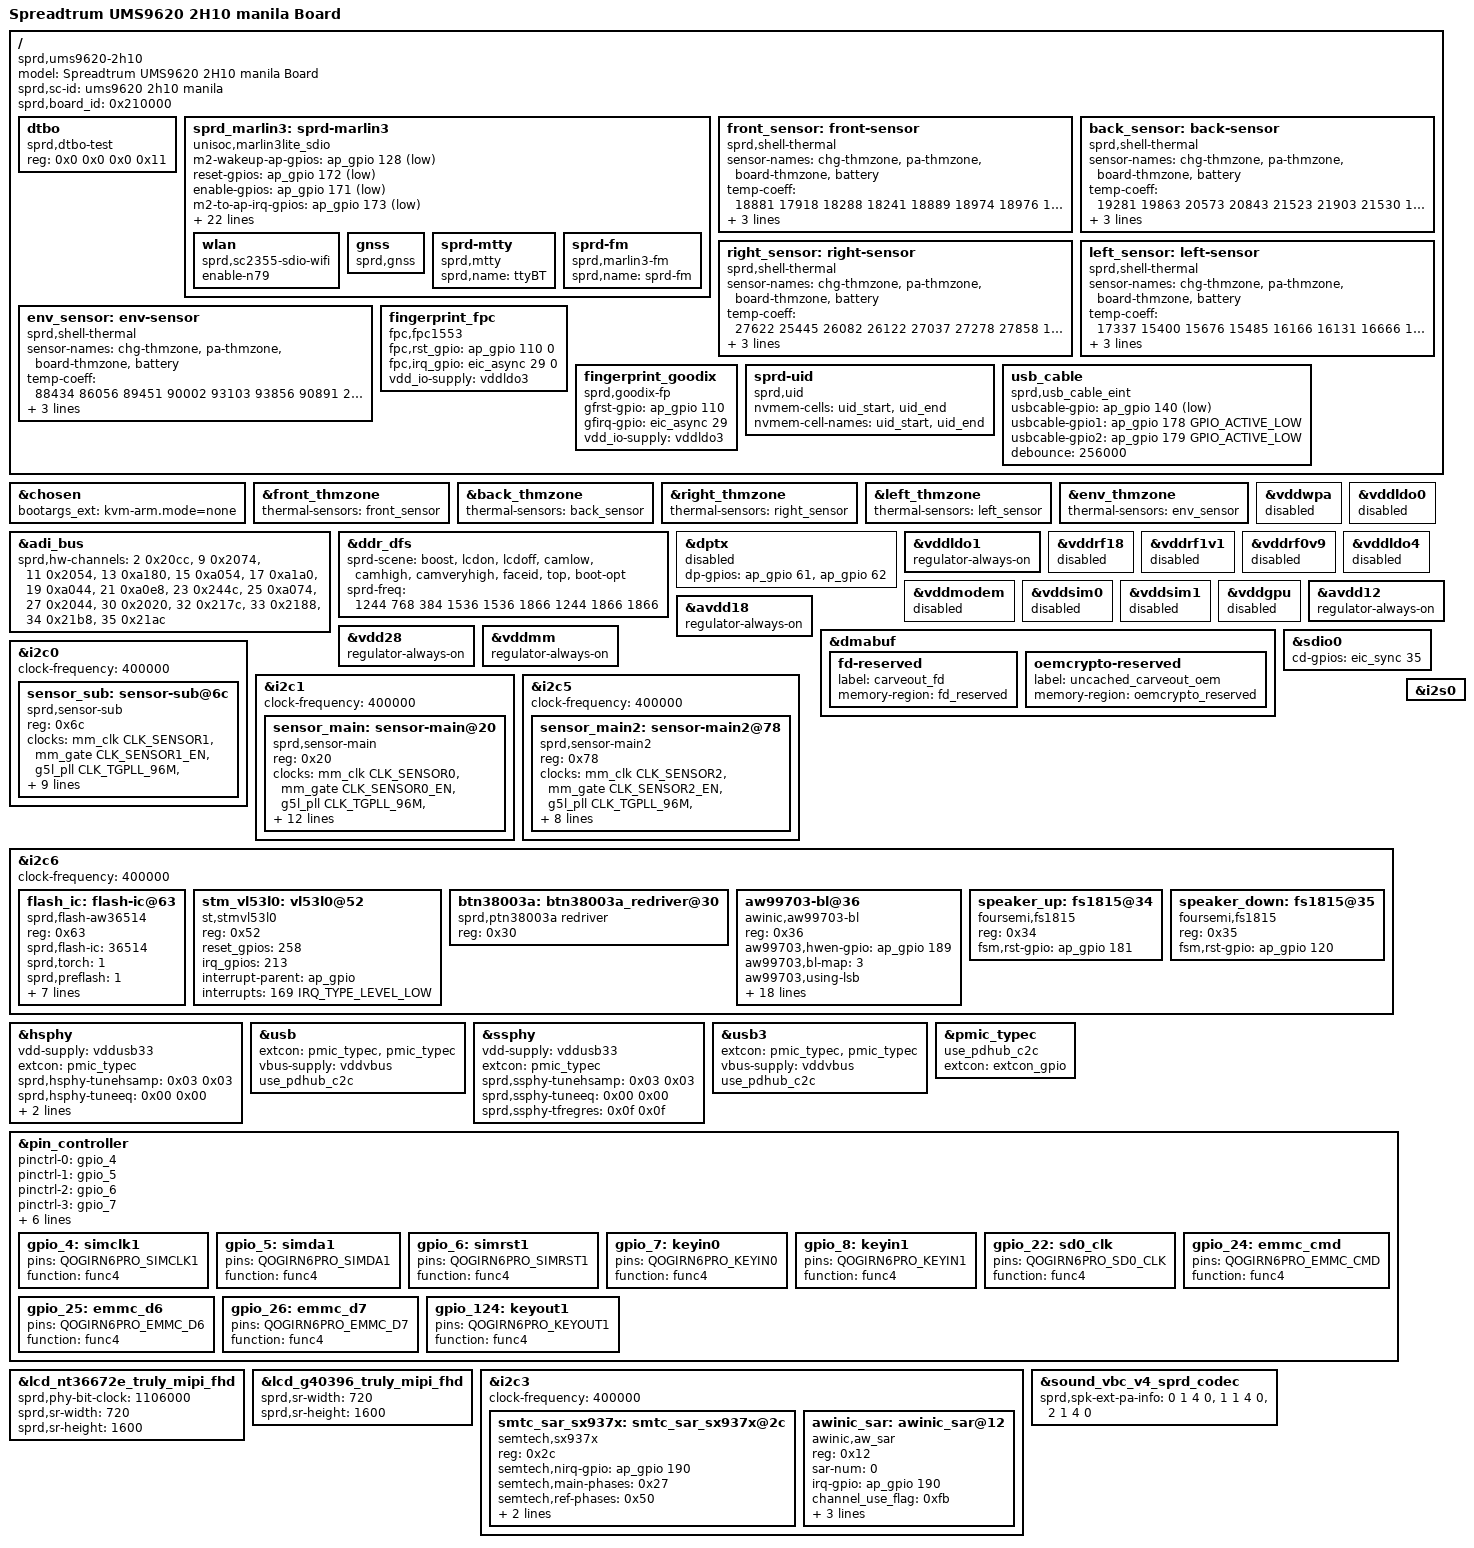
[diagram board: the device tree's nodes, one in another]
// SPDX-License-Identifier: (Licenseref-Unisoc-General-1.0 OR GPL-2.0-only)
/*
 * ums9620-2h10-overlay.dts - Unisoc platform device
 *
 * Copyright 2022 Unisoc(Shanghai) Technologies Co.Ltd
 *
 * Licensed under the Unisoc General Software License, version 1.0 (the
 * License);
 * you may not use this file except in compliance with the License.
 * You may obtain a copy of the License at
 * https://www.unisoc.com/en_us/license/UNISOC_GENERAL_LICENSE_V1.0-EN_US
 * Software distributed under the License is distributed on an "AS IS" BASIS,
 * WITHOUT WARRANTIES OF ANY KIND, either express or implied.
 * See the Unisoc General Software License, version 1.0 for more details.
 *
 * Alternatively you can use and distribute this file under the terms of the
 * GNU General Public License version 2, provided that it has to be used
 *  (including but not limited to combining, linking) with any other file under
 * the GNU General Public License version 2 on platforms that use Unisoc Chips.
 */

/dts-v1/;
/plugin/;
#include <dt-bindings/gpio/gpio.h>
#include <dt-bindings/interrupt-controller/arm-gic.h>
#include <dt-bindings/clock/sprd,ums9620-clk.h>
#include <dt-bindings/usb/pd.h>
#include "lcd/amoled_g2667fp108ff_visionox_mipi_fhd.dtsi"
#include "lcd/lcd_g40396_truly_mipi_fhd.dtsi"
#include "lcd/lcd_nt36672e_truly_mipi_fhd.dtsi"
#include "lcd/lcd_nt36672c_truly_mipi_fhd.dtsi"
#include "lcd/lcd_td4320_truly_mipi_fhd.dtsi"
#include "lcd/lcd_td4375_dijin_4lane_mipi_fhd.dtsi"
#include "lcd/lcd_ili9883c_txd_120hz_mipi_hd.dtsi"
#include "lcd/lcd_dummy_mipi.dtsi"
#include "reserved-memory/ums9620-2h10-overlay.dtsi"
#include "touchscreen/ums9620-spi1-gpio13-14-tp.dtsi"
#include "battery/ums9620-2h10_manila-overlay.dtsi"
#include "sound/ums9620-overlay.dtsi"
#include <dt-bindings/mfd/sprd,ump9620-regs.h>
#include <dt-bindings/mfd/sprd,ump9620-mask.h>
#include <dt-bindings/input/input.h>
#include <dt-bindings/clock/sprd,ums9620-clk.h>
#include "wcn/wcn_modules.h"
#include "wcn/interface/wcn-sdio-register.dtsi"
#include "wcn/chip/wcn-marlin3lite-umw2652-register.dtsi"

/ {

	model = "Spreadtrum UMS9620 2H10 manila Board"; // ONTIM

	compatible = "sprd,ums9620-2h10", "sprd,ums9620";

	sprd,sc-id = "ums9620 2h10 manila"; // ONTIM

	sprd,board_id = <0x210000>; //XXYY00:base board,XXYY00~XXYYFF:customize board

	fragment {
		target-path = "/";
		__overlay__ {
			#address-cells = <2>;
			#size-cells = <2>;

			model = "Spreadtrum UMS9620 2H10 manila Board"; // ONTIM
			sprd,sc-id = "ums9620 2h10 manila"; // ONTIM

			dtbo: dtbo {
				compatible = "sprd,dtbo-test";
				reg = <0x0 0x0 0x0 0x11>;
			};
			sprd_marlin3: sprd-marlin3 {
				compatible = "unisoc,marlin3lite_sdio";
				m2-wakeup-ap-gpios = <&ap_gpio 128 GPIO_ACTIVE_LOW>;
				reset-gpios = <&ap_gpio 172 GPIO_ACTIVE_LOW>;
				enable-gpios = <&ap_gpio 171 GPIO_ACTIVE_LOW>;
				m2-to-ap-irq-gpios = <&ap_gpio 173 GPIO_ACTIVE_LOW>;
				/* xtal-26m-clk-type = "TCXO"; */
				avdd12-supply = <&vddwcn>;
				avdd33-supply = <&vddwifipa>;
				dcxo18-supply = <&vddsim2>;
				clock-names = "clk_32k","source","enable";
				clocks = <&aonapb_gate CLK_AUX0>,
					 <&ext_32k>,
					 <&aonapb_gate CLK_AUX0_EB>;
				extcon = <&sdio1>;
				sdhci-name = <&sdio1>;
				sprd,check-emmc-ufs = "need_to_check_emmc_or_ufs";
				sprd,btwf-file-name = "/dev/block/by-name/wcnmodem";
				sprd,gnss-file-name = "/vendor/firmware/gnssmodem.bin";
				btwf-wakeup-lock;
				adma-tx;
				adma-rx;
				n79-mode-support;
				/*
				 * bound parameter:
				 * [0]:addr offset, [1]:mask, [2]:unboundval, [3]:boundval
				 */
				avdd12-parent-bound-chip = <REG_ANA_SLP_DCDC_PD_CTRL MASK_ANA_SLP_DCDCGEN1_PD_EN 0x0 MASK_ANA_SLP_DCDCGEN1_PD_EN>;
				avdd12-bound-wbreq = <REG_ANA_LDO_XTL_EN10 MASK_ANA_LDO_VDDWCN_EXT_XTL3_EN 0x0 MASK_ANA_LDO_VDDWCN_EXT_XTL3_EN>;
				avdd33-bound-wbreq = <REG_ANA_LDO_XTL_EN11 MASK_ANA_LDO_VDDWIFIPA_EXT_XTL3_EN 0x0 MASK_ANA_LDO_VDDWIFIPA_EXT_XTL3_EN>;

				wlan {
					compatible = "sprd,sc2355-sdio-wifi";
					enable-n79;
				};

				gnss {
					compatible = "sprd,gnss";
				};

				sprd-mtty {
					compatible = "sprd,mtty";
					sprd,name = "ttyBT";
				};

				sprd-fm {
					compatible = "sprd,marlin3-fm";
					sprd,name = "sprd-fm";
				};
			};

			front_sensor: front-sensor {
				compatible = "sprd,shell-thermal";
				#thermal-sensor-cells = <0>;
				sensor-names = "chg-thmzone",
						"pa-thmzone",
						"board-thmzone",
						"battery";
				temp-coeff = <18881 17918 18288 18241 18889 18974 18976
						13160 17177 17571 17413 17324 17990 23386
						15219 15341 15299 15330 14777 13891 16130
						597 16326 16001 15710 19060 19947 38182>;
				coeff-offset = <17000>;
				temp-const = <256>;
				const-offset = <0>;
			};

			back_sensor: back-sensor {
				compatible = "sprd,shell-thermal";
				#thermal-sensor-cells = <0>;
				sensor-names = "chg-thmzone",
						"pa-thmzone",
						"board-thmzone",
						"battery";
				temp-coeff = <19281 19863 20573 20843 21523 21903 21530
						15641 19803 20542 20460 20374 21149 27280
						20678 19833 19152 18770 18146 17276 19273
						521 18852 18577 18451 22329 23133 44243>;
				coeff-offset = <20000>;
				temp-const = <791>;
				const-offset = <1000>;
			};

			right_sensor: right-sensor {
				compatible = "sprd,shell-thermal";
				#thermal-sensor-cells = <0>;
				sensor-names = "chg-thmzone",
						"pa-thmzone",
						"board-thmzone",
						"battery";
				temp-coeff = <27622 25445 26082 26122 27037 27278 27858
						16966 24115 24729 24593 24441 25423 32621
						20953 21210 21364 21195 20328 19033 21485
						760 22980 22690 22546 26582 27761 52778>;
				coeff-offset = <24000>;
				temp-const = <805>;
				const-offset = <1000>;
			};

			left_sensor: left-sensor {
				compatible = "sprd,shell-thermal";
				#thermal-sensor-cells = <0>;
				sensor-names = "chg-thmzone",
						"pa-thmzone",
						"board-thmzone",
						"battery";
				temp-coeff = <17337 15400 15676 15485 16166 16131 16666
						10227 14360 14697 14516 14422 14890 19470
						11164 11541 12008 12157 11494 10590 12498
						229 13686 13382 12645 15805 16673 32684>;
				coeff-offset = <14000>;
				temp-const = <12>;
				const-offset = <0>;
			};

			env_sensor: env-sensor {
				compatible = "sprd,shell-thermal";
				#thermal-sensor-cells = <0>;
				sensor-names = "chg-thmzone",
						"pa-thmzone",
						"board-thmzone",
						"battery";
				temp-coeff = <88434 86056 89451 90002 93103 93856 90891
						28750 79653 85395 85323 84382 87994 125132
						71347 69498 67250 65976 63148 60212 71661
						425 73750 73214 74213 87331 89947 173603>;
				coeff-offset = <80000>;
				temp-const = <681>;
				const-offset = <3000>;
			};

			/*fingerprint@0 {
				compatible = "microarray,afs121";
				fpint-gpios = <&eic_async 29 0>;
  			};*/

			fingerprint_fpc {
				compatible = "fpc,fpc1553";
				fpc,rst_gpio    = <&ap_gpio 110 0>;
				fpc,irq_gpio    = <&eic_async 29 0>;
				vdd_io-supply   = <&vddldo3>;
  			};

			fingerprint_goodix {
				compatible = "sprd,goodix-fp";
				gfrst-gpio = <&ap_gpio 110 0>;
				gfirq-gpio = <&eic_async 29 0>;
				vdd_io-supply = <&vddldo3>;
			};

			sprd-uid {
				compatible = "sprd,uid";
				nvmem-cells = <&uid_start>, <&uid_end>;
				nvmem-cell-names = "uid_start", "uid_end";
			};

			usb_cable: usb_cable {
                		compatible = "sprd,usb_cable_eint";
                		usbcable-gpio = <&ap_gpio 140 GPIO_ACTIVE_LOW>;
                		usbcable-gpio1 = <&ap_gpio 178 GPIO_ACTIVE_LOW>;
                		usbcable-gpio2 = <&ap_gpio 179 GPIO_ACTIVE_LOW>;
                		debounce = <256000>;
                		status = "okay";
        		};

		};
	};
};

&chosen {
	bootargs_ext = "kvm-arm.mode=none";
};

&front_thmzone {
	status = "okay";
	thermal-sensors = <&front_sensor>;
};

&back_thmzone {
	status = "okay";
	thermal-sensors = <&back_sensor>;
};

&right_thmzone {
	status = "okay";
	thermal-sensors = <&right_sensor>;
};

&left_thmzone {
	status = "okay";
	thermal-sensors = <&left_sensor>;
};

&env_thmzone {
	status = "okay";
	thermal-sensors = <&env_sensor>;
};

&adi_bus {
	sprd,hw-channels = <2 0x20cc>, <9 0x2074>, <11 0x2054>, <13 0xa180>,
			<15 0xa054>, <17 0xa1a0>, <19 0xa044>, <21 0xa0e8>,
			<23 0x244c>, <25 0xa074>, <27 0x2044>, <30 0x2020>,
			<32 0x217c>, <33 0x2188>, <34 0x21b8>, <35 0x21ac>;
};

&ddr_dfs {
		sprd-scene = "boost", "lcdon", "lcdoff", "camlow",
			"camhigh", "camveryhigh", "faceid", "top", "boot-opt";
		sprd-freq = <1244 768 384 1536 1536 1866 1244 1866 1866>;
};

&dptx {
	dp-gpios = <&ap_gpio 61 GPIO_ACTIVE_HIGH>,
			<&ap_gpio 62 GPIO_ACTIVE_HIGH>;
	status = "disabled";
};

&vddwpa {
	status = "disabled";
};

&vddldo0 {
	status = "disabled";
};

&vddldo1 {
	regulator-always-on;
};

&vddrf18 {
	status = "disabled";
};

&vddrf1v1 {
	status = "disabled";
};

&vddrf0v9 {
	status = "disabled";
};

&vddldo4 {
	status = "disabled";
};

&vddmodem {
	status = "disabled";
};

&vddsim0 {
	status = "disabled";
};

&vddsim1 {
	status = "disabled";
};

&vddgpu {
	status = "disabled";
};

&avdd12 {
	regulator-always-on;
};

&avdd18 {
	regulator-always-on;
};

&vdd28 {
	regulator-always-on;
};

&vddmm {
	regulator-always-on;
};

&dmabuf {

	fd-reserved {
		label = "carveout_fd";
		memory-region = <&fd_reserved>;
	};

	oemcrypto-reserved {
		label = "uncached_carveout_oem";
		memory-region = <&oemcrypto_reserved>;
	};
};

&sdio0 {
	cd-gpios = <&eic_sync 35 GPIO_ACTIVE_HIGH>;
};

&i2c0 {
	status = "okay";
	clock-frequency = <400000>;

	sensor_sub: sensor-sub@6c {
		compatible = "sprd,sensor-sub";
		reg = <0x6c>;
		clock-names = "clk_src","sensor_eb",
			"clk_96m","clk_64m",
			"clk_51m2","clk_48m","clk_26m";
		clocks = <&mm_clk CLK_SENSOR1>,<&mm_gate CLK_SENSOR1_EN>,
			<&g5l_pll CLK_TGPLL_96M>,<&g5l_pll CLK_TGPLL_64M>,
			<&g5l_pll CLK_TGPLL_51M2>,<&g5l_pll CLK_TGPLL_48M>,<&ext_26m>;

		vddio-supply = <&vddcamio>;
		vddcama-supply = <&vddcama1>;
		vddcamd-supply = <&vddcamd1>;
		reset-gpios = <&ap_gpio 39 0>;
		//power-down-gpios = <&ap_gpio 45 0>;
		sprd,phyid = <1>;
		csi = <&csi1>;
	};
};

&i2c1 {
	status = "okay";
	clock-frequency = <400000>;

	sensor_main: sensor-main@20 {
		compatible = "sprd,sensor-main";
		reg = <0x20>;
		clock-names = "clk_src","sensor_eb",
			"clk_96m","clk_64m",
			"clk_51m2","clk_48m","clk_26m";
		clocks = <&mm_clk CLK_SENSOR0>,<&mm_gate CLK_SENSOR0_EN>,
				<&g5l_pll CLK_TGPLL_96M>,<&g5l_pll CLK_TGPLL_64M>,
				<&g5l_pll CLK_TGPLL_51M2>,<&g5l_pll CLK_TGPLL_48M>,<&ext_26m>;
		vddio-supply = <&vddcamio>;
		vddcama-supply = <&vddcama0>;
		vddcamd-supply = <&vddcamd0>;
		//dvdd-gpios = <&ap_gpio 81 0>;
		vddcamois-supply = <&vddcammot1>;
		vddcammot-supply = <&vddcammot0>;
		reset-gpios = <&ap_gpio 40 0>;
		//power-down-gpios = <&ap_gpio 46 0>;
		power-domains = <&mm_domain>;
		sprd,phyid = <0>;
		csi = <&csi0>;
	};
};

&i2c5 {
	status = "okay";
	clock-frequency = <400000>;

	sensor_main2: sensor-main2@78 {
		compatible = "sprd,sensor-main2";
		reg = <0x78>;
		clock-names = "clk_src","sensor_eb",
			"clk_96m","clk_64m",
			"clk_51m2","clk_48m","clk_26m";
		clocks = <&mm_clk CLK_SENSOR2>,<&mm_gate CLK_SENSOR2_EN>,
			<&g5l_pll CLK_TGPLL_96M>,<&g5l_pll CLK_TGPLL_64M>,
			<&g5l_pll CLK_TGPLL_51M2>,<&g5l_pll CLK_TGPLL_48M>,<&ext_26m>;
		vddio-supply = <&vddcamio>;
		vddcama-supply = <&vddcama2>;
		//vddcamd-supply = <&vddcamd2>;
		reset-gpios = <&ap_gpio 41 0>;
		//power-down-gpios = <&ap_gpio 48 0>;
		sprd,phyid = <6>;
		csi = <&csi3>;
	};
};

&i2c6 {
	status = "okay";
	clock-frequency = <400000>;

	flash_ic: flash-ic@63 {
		compatible = "sprd,flash-aw36514","sprd,flash-ocp81375";
		reg = <0x63>;
		sprd,flash-ic = <36514>;
		sprd,torch = <1>;
		sprd,preflash = <1>;
		sprd,highlight = <1>;
		sprd,torch-level = <128>;
		sprd,preflash-level = <128>;
		sprd,highlight-level = <128>;
		sprd,lvfm-enable = <1>;
		//flash-torch-en-gpios = <&ap_gpio 112 0>;
		flash-chip-en-gpios = <&ap_gpio 119 0>;
		//flash-en-gpios = <&ap_gpio 111 0>;
		flash-sync-gpios = <&ap_gpio 177 0>;
	};

	stm_vl53l0: vl53l0@52 {
		compatible = "st,stmvl53l0";
		reg = <0x52>;
		reset_gpios = <258>;
		irq_gpios = <213>;
		interrupt-parent = <&ap_gpio>;
		interrupts = <169 IRQ_TYPE_LEVEL_LOW>;
	};

	btn38003a: btn38003a_redriver@30 {
		compatible = "sprd,ptn38003a redriver";
		reg = <0x30>;
	};

	aw99703-bl@36 {
		compatible = "awinic,aw99703-bl";
		status = "okay";
		reg = <0x36>;
		aw99703,hwen-gpio = <&ap_gpio 189 0>;
		/* brightness map level 1:256,2:1024,3:2048 */
		aw99703,bl-map = <3>;
		aw99703,using-lsb;
		aw99703,ovp-level = <3>; /* 38V(default) */
		aw99703,ocp-level = <2>; /* 2.7A(default) */
		aw99703,switch-freq = <1>; /* 1000kHz(default) */
		aw99703,auto-freq-high = <0x80>;
		aw99703,auto-freq-low = <0x10>;
		aw99703,bl-fscal-led = <0x1F>; /* 29.6mA(default) */
		aw99703,bl-channel = <3>;
		aw99703,turn-on-ramp = <0x04>; /* 8ms(default) */
		aw99703,turn-off-ramp = <0x04>; /* 8ms(default) */
		aw99703,pwm-trans-dim = <0>; /* 2ms(default) */
		aw99703,i2c-trans-dim = <0>; /* 1us(default) */
		aw99703,pwm-mode = <0>; /* 0 pwm enable,1 PWM disable */
		aw99703,map-type = <1>; /* linear */
		aw99703,work-mode = <1>; /* backlight */
		aw99703,flash-timeout-time = <0x05>; /* 500ms(default) */
		aw99703,flash-current = <0x08>; /* 59.2mA(default) */
		aw99703,efuse-config = <0x1C 0x61 0x61 0x4C 0x2C 0xC0 0x08 0x00 0x01 0xC0 0x00 0x00 0x50>;
	};

	// Speaker up
	speaker_up: fs1815@34 {
		compatible = "foursemi,fs1815";
		reg = <0x34>;
		fsm,rst-gpio = <&ap_gpio 181 0>;
		status = "okay";
	};

	// Speaker down
	speaker_down: fs1815@35 {
		compatible = "foursemi,fs1815";
		reg = <0x35>;
		fsm,rst-gpio = <&ap_gpio 120 0>;
		status = "okay";
	};
};

&hsphy {
	vdd-supply = <&vddusb33>;
	extcon = <&pmic_typec>;
	/* first value is reserverd, the second is host */
	sprd,hsphy-tunehsamp = /bits/ 8 <0x03 0x03>;
	sprd,hsphy-tuneeq = /bits/ 8 <0x00 0x00>;
	sprd,hsphy-tfregres = /bits/ 8 <0x0f 0x0f>;
	/* avdd1v8 always off */
	avdd1v8-always-off;
	status = "okay";
};

&usb {
	extcon = <&pmic_typec>, <&pmic_typec>;
	vbus-supply = <&vddvbus>;
	status = "okay";
	use_pdhub_c2c;
};

&ssphy {
	vdd-supply = <&vddusb33>;
	extcon = <&pmic_typec>;
	/* first value is device eye-patt setting, the second is host */
	sprd,ssphy-tunehsamp = /bits/ 8 <0x03 0x03>;
	sprd,ssphy-tuneeq = /bits/ 8 <0x00 0x00>;
	sprd,ssphy-tfregres = /bits/ 8 <0x0f 0x0f>;
	status = "okay";
};

&usb3 {
	extcon = <&pmic_typec>, <&pmic_typec>;
	vbus-supply = <&vddvbus>;
	status = "okay";
	use_pdhub_c2c;
};

&pmic_typec {
	use_pdhub_c2c;
	extcon = <&extcon_gpio>;
	status = "okay";
};

&pin_controller {
	pinctrl-names =
	/* IM1_CLK ,SIM1_DA ,SIM1_RST ,keyin0 */
	 "gpio_4", "gpio_5", "gpio_6", "gpio_7",
	/* keyin1 ,sd0_clk, emmc_cmd */
	"gpio_8", "gpio_22", "gpio_24",
	/* emmc_d6, emmc_d7, emmc_d7 */
	"gpio_25", "gpio_26", "gpio_124";

	pinctrl-0 = <&gpio_4>;
	pinctrl-1 = <&gpio_5>;
	pinctrl-2 = <&gpio_6>;
	pinctrl-3 = <&gpio_7>;
	pinctrl-4 = <&gpio_8>;
	pinctrl-5 = <&gpio_22>;
	pinctrl-6 = <&gpio_24>;
	pinctrl-7 = <&gpio_25>;
	pinctrl-8 = <&gpio_26>;
	pinctrl-9 = <&gpio_124>;

	gpio_4: simclk1 {
		pins = "QOGIRN6PRO_SIMCLK1";
		function = "func4";
	};

	gpio_5: simda1 {
		pins = "QOGIRN6PRO_SIMDA1";
		function = "func4";
	};

	gpio_6: simrst1 {
		pins = "QOGIRN6PRO_SIMRST1";
		function = "func4";
	};

	gpio_7: keyin0 {
		pins = "QOGIRN6PRO_KEYIN0";
		function = "func4";
	};

	gpio_8: keyin1 {
		pins = "QOGIRN6PRO_KEYIN1";
		function = "func4";
	};

	gpio_22: sd0_clk {
		pins = "QOGIRN6PRO_SD0_CLK";
		function = "func4";
	};

	gpio_24: emmc_cmd {
		pins = "QOGIRN6PRO_EMMC_CMD";
		function = "func4";
	};

	gpio_25: emmc_d6 {
		pins = "QOGIRN6PRO_EMMC_D6";
		function = "func4";
	};

	gpio_26: emmc_d7 {
		pins = "QOGIRN6PRO_EMMC_D7";
		function = "func4";
	};

	gpio_124: keyout1 {
		pins = "QOGIRN6PRO_KEYOUT1";
		function = "func4";
	};
};

&lcd_nt36672e_truly_mipi_fhd {
	sprd,phy-bit-clock = <1106000>;
	sprd,sr-width = <720>;
	sprd,sr-height = <1600>;
};

&lcd_g40396_truly_mipi_fhd {
	sprd,sr-width = <720>;
	sprd,sr-height = <1600>;
};

&i2c3 {
	status = "okay";
	clock-frequency = <400000>;

	smtc_sar_sx937x:smtc_sar_sx937x@2c {
		compatible = "semtech,sx937x";
		reg = <0x2c>;
		status = "okay";
		semtech,nirq-gpio = <&ap_gpio 190 GPIO_ACTIVE_HIGH>;
		/*
		semtech,nirq-gpio = <&pio 3 0>;
		pinctrl-names = "smtc_pins_default", "smtc_sar_int_active";
		pinctrl-0 = <&smtc_pins_default>;
		pinctrl-1 = <&smtc_sar_int_active>;
		*/
		/*main-phases: Phases(aka CH) connected to the antenas for measurement
		ref-phases: Phases used as temperature reference correction
		Each bit represents a corresponding phase is for this usage(1) or not(0)
		Example: 0xF = 0b1 1111, indicates PH0/1/2/3/4 are used as main phase.
				 0x30 = 0b0110 0000 indicates PH5/6 are used as reference phase.
		*/
		semtech,main-phases = <0x27>;
		semtech,ref-phases = <0x50>;

		semtech,reg-init = <
			0x8024 0x7F00
			0x4004 0x70
			0x4008 0x8
			0x8020 0x32
			0x8028 0x85E
			0x8034 0x85E
			0x8040 0x85E
			0x804C 0x85E
			0x8058 0x85E
			0x8064 0x85E
			0x8070 0x85E
			0x807C 0x85E
			0x8030 0x924925
			0x803C 0x92492C
			0x8048 0x924964
			0x8054 0x924925
			0x8060 0x925924
			0x806C 0x92C924
			0x8078 0x964924
			0x8084 0xB24924
			0x8098 0xC88E
			0x80B8 0xC88E
			0x80D8 0xC88E
			0x80F8 0xC88E
			0x8118 0xC88E
			0x8138 0xC88E
			0x8158 0xC88E
			0x8178 0xC88E
			0x8090 0x54AC5000
			0x80B0 0x54AC5000
			0x80D0 0x54AC5000
			0x80F0 0x54AC5000
			0x8110 0x54AC5000
			0x8130 0x54AC5000
			0x8150 0x54AC5000
			0x8170 0x54AC5000
			0x8088 0x3100000
			0x80A8 0x3100000
			0x80C8 0x3100000
			0x80E8 0x3100000
			0x8108 0x3100000
			0x8128 0x3100000
			0x8148 0x3100000
			0x8168 0x3100000
			0x808C 0x60200030
			0x80AC 0x60200030
			0x80CC 0x60200030
			0x80EC 0x60200030
			0x810C 0x60200030
			0x812C 0x60200030
			0x814C 0x60200030
			0x816C 0x60200030
			0x8274 0x2E040000
			0x8024 0x7f20
		>;
	};

	awinic_sar:awinic_sar@12 {
		compatible = "awinic,aw_sar";
		reg = <0x12>;
		sar-num = < 0 >;
		irq-gpio = <&ap_gpio 190 GPIO_ACTIVE_HIGH>;
		/*
		interrupt-parent = < &tlmm >;
		interrupts = <72 0>;
		irq-gpio = <&tlmm 72 0>;
		*/
		//vcc0-supply = <&pm660l_l4>;
		channel_use_flag = <0xfb>;
		aw_sar,update_fw;
		/* private node belongs to aw963xx */
		start-mode = < 1 >; // 0: start in rom  1: start in ram
		irq-mux = < 2 >; // set csx as irq pin. config this field when connect to aw96308/aw96310
		status = "okay";
	};
};

&i2s0 {
	status = "okay";
};

&sound_vbc_v4_sprd_codec {
	status = "okay";
	sprd,spk-ext-pa-info = <0 1 4 0>,<1 1 4 0>,<2 1 4 0>;
};
